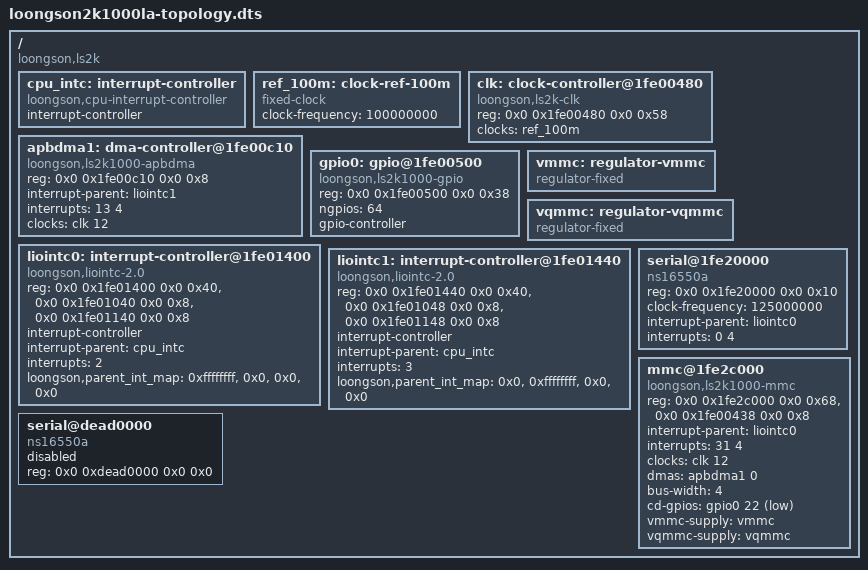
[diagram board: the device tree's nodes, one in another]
/dts-v1/;

/ {
    compatible = "loongson,ls2k";
    #address-cells = <2>;
    #size-cells = <2>;

    cpu_intc: interrupt-controller {
        compatible = "loongson,cpu-interrupt-controller";
        interrupt-controller;
        #interrupt-cells = <1>;
    };

    ref_100m: clock-ref-100m {
        compatible = "fixed-clock";
        #clock-cells = <0>;
        clock-frequency = <100000000>;
    };

    clk: clock-controller@1fe00480 {
        compatible = "loongson,ls2k-clk";
        reg = <0x0 0x1fe00480 0x0 0x58>;
        #clock-cells = <1>;
        clocks = <&ref_100m>;
        clock-names = "ref_100m";
    };

    apbdma1: dma-controller@1fe00c10 {
        compatible = "loongson,ls2k1000-apbdma";
        reg = <0x0 0x1fe00c10 0x0 0x8>;
        interrupt-parent = <&liointc1>;
        interrupts = <13 4>;
        clocks = <&clk 12>;
        #dma-cells = <1>;
    };

    gpio0: gpio@1fe00500 {
        compatible = "loongson,ls2k1000-gpio", "loongson,ls2k-gpio";
        reg = <0x0 0x1fe00500 0x0 0x38>;
        ngpios = <64>;
        gpio-controller;
        #gpio-cells = <2>;
    };

    vmmc: regulator-vmmc {
        compatible = "regulator-fixed";
    };

    vqmmc: regulator-vqmmc {
        compatible = "regulator-fixed";
    };

    liointc0: interrupt-controller@1fe01400 {
        compatible = "loongson,liointc-2.0";
        reg = <0x0 0x1fe01400 0x0 0x40>,
              <0x0 0x1fe01040 0x0 0x8>,
              <0x0 0x1fe01140 0x0 0x8>;
        reg-names = "main", "isr0", "isr1";
        interrupt-controller;
        #interrupt-cells = <2>;
        interrupt-parent = <&cpu_intc>;
        interrupts = <2>;
        interrupt-names = "int0";
        loongson,parent_int_map = <0xffffffff>, <0x0>, <0x0>, <0x0>;
    };

    liointc1: interrupt-controller@1fe01440 {
        compatible = "loongson,liointc-2.0";
        reg = <0x0 0x1fe01440 0x0 0x40>,
              <0x0 0x1fe01048 0x0 0x8>,
              <0x0 0x1fe01148 0x0 0x8>;
        reg-names = "main", "isr0", "isr1";
        interrupt-controller;
        #interrupt-cells = <2>;
        interrupt-parent = <&cpu_intc>;
        interrupts = <3>;
        interrupt-names = "int1";
        loongson,parent_int_map = <0x0>, <0xffffffff>, <0x0>, <0x0>;
    };

    serial@1fe20000 {
        compatible = "ns16550a";
        reg = <0x0 0x1fe20000 0x0 0x10>;
        clock-frequency = <125000000>;
        interrupt-parent = <&liointc0>;
        interrupts = <0 4>;
    };

    mmc@1fe2c000 {
        compatible = "loongson,ls2k1000-mmc";
        reg = <0x0 0x1fe2c000 0x0 0x68>,
              <0x0 0x1fe00438 0x0 0x8>;
        interrupt-parent = <&liointc0>;
        interrupts = <31 4>;
        clocks = <&clk 12>;
        dmas = <&apbdma1 0>;
        dma-names = "rx-tx";
        bus-width = <4>;
        cd-gpios = <&gpio0 22 1>;
        vmmc-supply = <&vmmc>;
        vqmmc-supply = <&vqmmc>;
    };

    serial@dead0000 {
        compatible = "ns16550a";
        status = "disabled";
        reg = <0x0 0xdead0000 0x0 0x0>;
    };
};
